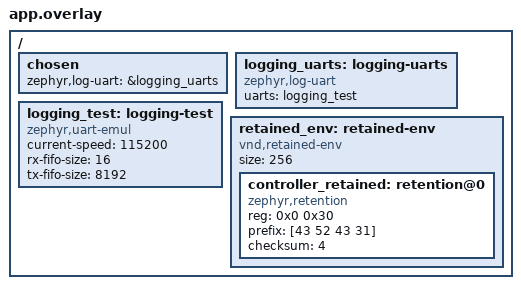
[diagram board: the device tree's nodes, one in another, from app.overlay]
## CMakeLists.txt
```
# SPDX-License-Identifier: Apache-2.0

# The scenario of the controller framework on native_sim with no watchdog and the option that allows
# operation without one: a startup step that passes its deadline ends in a software reset, and the
# next boot reports the record. The framework is the Zephyr module of this repository with health
# supervision only; this file names no source or include directory of the module. The test-only
# retained memory and the helpers of the scenarios are in ../common.

cmake_minimum_required(VERSION 3.20.0)
list(APPEND DTS_ROOT "${CMAKE_CURRENT_LIST_DIR}/../common")
find_package(Zephyr REQUIRED HINTS $ENV{ZEPHYR_BASE})
project(controller_framework_no_watchdog_native_sim LANGUAGES C)

if(NOT CONFIG_BOARD_NATIVE_SIM)
    message(FATAL_ERROR "This scenario is restricted to native_sim")
endif()
if(NOT CONFIG_CRUX_CONTROLLER_FRAMEWORK_SUPERVISION OR NOT CONFIG_CRUX_CONTROLLER_START_WITHOUT_WATCHDOG
   OR NOT CONFIG_CRUX_CONTROLLER_FRAMEWORK_FAULT_INJECTION OR CONFIG_CRUX_SYSTEM_NATIVE_SIM_WATCHDOG)
    message(FATAL_ERROR "The scenario needs supervision without a watchdog, the option that allows it, and fault injection")
endif()

target_sources(app PRIVATE src/test_no_watchdog.c ../common/scenario.c ../common/retained_env.c)
target_include_directories(app PRIVATE ../common)
target_link_libraries(app PRIVATE controller::framework)
```

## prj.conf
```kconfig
# The scenario of the controller framework with no watchdog (criterion 7, second part): health
# supervision only, without web management, the command line or time synchronisation, on Crux
# System with no watchdog behind the alias crux-watchdog0 and no simulated watchdog, with the
# option of decision D14 that allows operation without a watchdog. A restart goes through
# crux_system_reset(), which CONFIG_NATIVE_SIM_REBOOT turns into a restart of the simulated process.
CONFIG_CRUX_CONTROLLER_FRAMEWORK=y
CONFIG_CRUX_CONTROLLER_START_WITHOUT_WATCHDOG=y
CONFIG_CRUX_CONTROLLER_FRAMEWORK_FAULT_INJECTION=y
CONFIG_CRUX_CONTROLLER_SUPERVISOR_PERIOD_MS=500
CONFIG_CRUX_CONTROLLER_WATCHDOG_TIMEOUT_MS=2000
CONFIG_CRUX_CONTROLLER_DEADLINE_APPLICATION_MS=2000
CONFIG_CRUX_CONTROLLER_STABLE_PERIOD_S=3600
CONFIG_MAIN_THREAD_PRIORITY=8

CONFIG_CRUX_SYSTEM=y
CONFIG_WATCHDOG=y
CONFIG_HWINFO=y
CONFIG_REBOOT=y
CONFIG_NATIVE_SIM_REBOOT=y
CONFIG_TASK_WDT=y
CONFIG_TASK_WDT_HW_FALLBACK=n
CONFIG_RETAINED_MEM=y
CONFIG_RETAINED_MEM_MUTEX_FORCE_DISABLE=y
CONFIG_RETENTION=y
CONFIG_RETENTION_MUTEX_FORCE_DISABLE=y

# Crux Logging writes to an emulated UART, which the program copies to standard output.
CONFIG_CRUX_TIME=y
CONFIG_CRUX_LOGGING=y
CONFIG_SERIAL=y
CONFIG_EMUL=y
CONFIG_UART_EMUL=y
CONFIG_UART_INTERRUPT_DRIVEN=y
CONFIG_PICOLIBC=y
CONFIG_LOG=y
CONFIG_LOG_MODE_DEFERRED=y
CONFIG_LOG_MODE_OVERFLOW=n
CONFIG_LOG_BLOCK_IN_THREAD=n
CONFIG_LOG_PROCESS_THREAD=y
CONFIG_LOG_PROCESS_THREAD_CUSTOM_PRIORITY=y
CONFIG_LOG_PROCESS_THREAD_PRIORITY=14
CONFIG_LOG_BUFFER_SIZE=4096
CONFIG_LOG_MAX_LEVEL=4
CONFIG_LOG_DEFAULT_LEVEL=0
CONFIG_LOG_RUNTIME_FILTERING=n
CONFIG_LOG_BACKEND_UART=y
CONFIG_LOG_BACKEND_NATIVE_POSIX=n
CONFIG_LOG_BACKEND_UART_ASYNC=n
CONFIG_LOG_PRINTK=n
CONFIG_LOG_BACKEND_SHOW_LEVEL=y
CONFIG_LOG_BACKEND_CRLF_NONE=n
CONFIG_THREAD_MONITOR=y
CONFIG_THREAD_NAME=y
CONFIG_INIT_STACKS=y
CONFIG_THREAD_STACK_INFO=y
CONFIG_SHELL=n
```

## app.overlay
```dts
/* The scenario with no watchdog: Crux Logging on an emulated UART, which the program copies to
 * standard output, and the retained region over the test-only retained memory of ../common, which
 * keeps its bytes across a restart of the simulated process. No alias crux-watchdog0: Crux System
 * has no watchdog. */
/ {
    chosen { zephyr,log-uart = &logging_uarts; };
    logging_uarts: logging-uarts {
        compatible = "zephyr,log-uart";
        uarts = <&logging_test>;
    };
    logging_test: logging-test {
        compatible = "zephyr,uart-emul";
        current-speed = <115200>;
        rx-fifo-size = <16>;
        tx-fifo-size = <8192>;
        status = "okay";
    };

    retained_env: retained-env {
        compatible = "vnd,retained-env";
        size = <256>;
        status = "okay";
        #address-cells = <1>;
        #size-cells = <1>;

        controller_retained: retention@0 {
            compatible = "zephyr,retention";
            status = "okay";
            reg = <0x0 0x30>;
            prefix = [43 52 43 31];
            checksum = <4>;
        };
    };
};
```

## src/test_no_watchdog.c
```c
/* SPDX-License-Identifier: Apache-2.0 */

/* The scenario of the controller framework with no watchdog (criterion 7, second part). One run,
 * two boots. In the first, the application step, step 12, stalls past its deadline: the supervisor
 * latches the fault, writes the record and, with no armed watchdog, requests a software reset with
 * crux_system_reset(), which restarts the simulated process. The second boot reads the record,
 * which names the step, counts the reset as a fault reset, and, because the build allows operation
 * without a watchdog (D14), the controller is operational. */

#include <stdio.h>

#include <controller/framework.h>
#include <controller/framework_test.h>
#include <zephyr/kernel.h>

#include "scenario.h"

int main(void)
{
    char text[64];
    const int boot = scenario_boot_number();

    scenario_forward_log();
    (void)snprintf(text, sizeof text, "no watchdog scenario boot %d", boot);
    scenario_say(text);
    if (boot == 1) {
        (void)controller_framework_inject(CONTROLLER_FRAMEWORK_FAULT_STEP_STALL, "application");
    }
    if (controller_framework_start(NULL) != CONTROLLER_FRAMEWORK_OK) {
        scenario_say("no watchdog scenario FAILED: the start function");
    }
    if (boot == 2) {
        /* The controller state follows on the supervisor's next periods. */
        k_msleep(2000);
        scenario_say("no watchdog scenario done");
    }
    for (;;) {
        k_sleep(K_FOREVER);
    }
    return 0;
}
```
